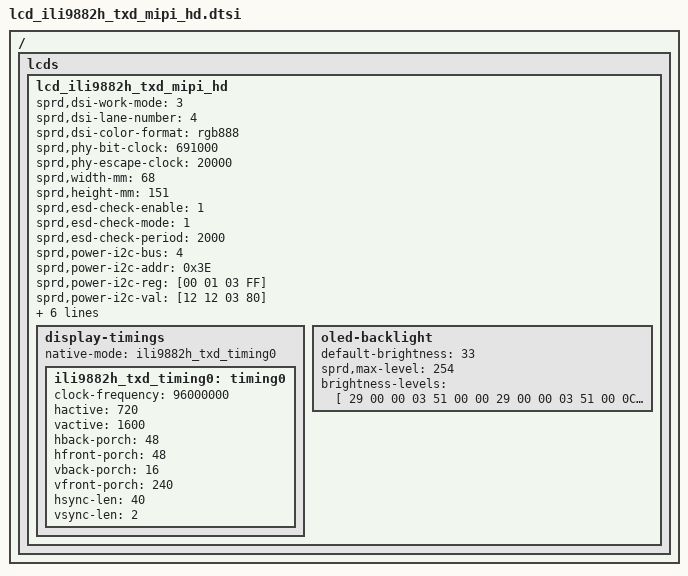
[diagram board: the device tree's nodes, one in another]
/*
 * ili9882h txd HD Scaling-Up LCD config dtsi file for spreadtrum
 *
 * Copyright (C) 2018, Spreadtrum Communications Inc.
 *
 * SPDX-License-Identifier: (GPL-2.0+ OR MIT)
 */

/ {
	fragment {
		target-path = "/";
		__overlay__ {
			lcds {
				lcd_ili9882h_txd_mipi_hd: lcd_ili9882h_txd_mipi_hd {
					sprd,dsi-work-mode = <3>; /* video burst mode*/
					sprd,dsi-lane-number = <4>;
					sprd,dsi-color-format = "rgb888";

					sprd,phy-bit-clock = <691000>;	/* kbps */    
					sprd,phy-escape-clock = <20000>;/* kHz */  

					sprd,width-mm = <68>;
					sprd,height-mm = <151>;
					
					sprd,esd-check-enable = <1>;
					sprd,esd-check-mode = <1>;
					sprd,esd-check-period = <2000>;
					//sprd,esd-check-register = <0xA>;
					//sprd,esd-check-value = <0x9c>;

					//sprd,use-oled-lp;

					sprd,power-i2c-bus = <4>;
        			sprd,power-i2c-addr = <0x3E>;
        			/*sprd,power-i2c-speed = <400000>;*/
        			sprd,power-i2c-reg = [00 01 03 FF];
        			sprd,power-i2c-val = [12 12 03 80];

					sprd,reset-on-sequence = <1 10>, <0 10>, <1 10>;
					sprd,reset-off-sequence = <1 10>;

					//sprd,use-dcs-write;

					sprd,initial-command = [
						29 00 00 04 FF 98 82 00
						13 00 00 02 35 00
						29 00 00 03 51 07 FF
						13 00 00 02 53 2C
						13 00 00 02 55 01
						03 3C 00 01 11
						29 00 00 04 FF 98 82 03
						29 00 00 02 83 B8
						29 00 00 04 FF 98 82 00
						03 14 00 01 29
						];

					sprd,sleep-in-command = [
						03 14 00 01 28
						03 78 00 01 10
						];

					display-timings {
						native-mode = <&ili9882h_txd_timing0>;

						ili9882h_txd_timing0: timing0 {
							clock-frequency = <96000000>;           
							hactive = <720>;
							vactive = <1600>;
							hback-porch = <48>;
							hfront-porch = <48>;
							vback-porch = <16>;
							vfront-porch = <240>;
							hsync-len = <40>;
							vsync-len = <2>;
						};
					};
			
					oled-backlight {			
						default-brightness = <33>;	
						sprd,max-level = <254>;
						brightness-levels = [				
            		    	29 00 00 03 51 00 00
							29 00 00 03 51 00 0C
							29 00 00 03 51 00 14
							29 00 00 03 51 00 1C
							29 00 00 03 51 00 25
							29 00 00 03 51 00 2D
							29 00 00 03 51 00 35
							29 00 00 03 51 00 3D
							29 00 00 03 51 00 45
							29 00 00 03 51 00 4D
							29 00 00 03 51 00 55
							29 00 00 03 51 00 5D
							29 00 00 03 51 00 65
							29 00 00 03 51 00 6D
							29 00 00 03 51 00 75
							29 00 00 03 51 00 7D
							29 00 00 03 51 00 85
							29 00 00 03 51 00 8D
							29 00 00 03 51 00 95
							29 00 00 03 51 00 9D
							29 00 00 03 51 00 A5
							29 00 00 03 51 00 AD
							29 00 00 03 51 00 B5
							29 00 00 03 51 00 BD
							29 00 00 03 51 00 C5
							29 00 00 03 51 00 CD
							29 00 00 03 51 00 D5
							29 00 00 03 51 00 DD
							29 00 00 03 51 00 E5
							29 00 00 03 51 00 EE
							29 00 00 03 51 00 F6
							29 00 00 03 51 00 FE
							29 00 00 03 51 01 06
							29 00 00 03 51 01 0E
							29 00 00 03 51 01 16
							29 00 00 03 51 01 1E
							29 00 00 03 51 01 26
							29 00 00 03 51 01 2E
							29 00 00 03 51 01 36
							29 00 00 03 51 01 3E
							29 00 00 03 51 01 46
							29 00 00 03 51 01 4E
							29 00 00 03 51 01 56
							29 00 00 03 51 01 5E
							29 00 00 03 51 01 66
							29 00 00 03 51 01 6E
							29 00 00 03 51 01 76
							29 00 00 03 51 01 7E
							29 00 00 03 51 01 86
							29 00 00 03 51 01 8E
							29 00 00 03 51 01 96
							29 00 00 03 51 01 9E
							29 00 00 03 51 01 A6
							29 00 00 03 51 01 AE
							29 00 00 03 51 01 B7
							29 00 00 03 51 01 BF
							29 00 00 03 51 01 C7
							29 00 00 03 51 01 CF
							29 00 00 03 51 01 D7
							29 00 00 03 51 01 DF
							29 00 00 03 51 01 E7
							29 00 00 03 51 01 EF
							29 00 00 03 51 01 F7
							29 00 00 03 51 01 FF
							29 00 00 03 51 02 07
							29 00 00 03 51 02 0F
							29 00 00 03 51 02 17
							29 00 00 03 51 02 1F
							29 00 00 03 51 02 27
							29 00 00 03 51 02 2F
							29 00 00 03 51 02 37
							29 00 00 03 51 02 3F
							29 00 00 03 51 02 47
							29 00 00 03 51 02 4F
							29 00 00 03 51 02 57
							29 00 00 03 51 02 5F
							29 00 00 03 51 02 67
							29 00 00 03 51 02 6F
							29 00 00 03 51 02 77
							29 00 00 03 51 02 80
							29 00 00 03 51 02 88
							29 00 00 03 51 02 90
							29 00 00 03 51 02 98
							29 00 00 03 51 02 A0
							29 00 00 03 51 02 A8
							29 00 00 03 51 02 B0
							29 00 00 03 51 02 B8
							29 00 00 03 51 02 C0
							29 00 00 03 51 02 C8
							29 00 00 03 51 02 D0
							29 00 00 03 51 02 D8
							29 00 00 03 51 02 E0
							29 00 00 03 51 02 E8
							29 00 00 03 51 02 F0
							29 00 00 03 51 02 F8
							29 00 00 03 51 03 00
							29 00 00 03 51 03 08
							29 00 00 03 51 03 10
							29 00 00 03 51 03 18
							29 00 00 03 51 03 20
							29 00 00 03 51 03 28
							29 00 00 03 51 03 30
							29 00 00 03 51 03 38
							29 00 00 03 51 03 40
							29 00 00 03 51 03 49
							29 00 00 03 51 03 51
							29 00 00 03 51 03 59
							29 00 00 03 51 03 61
							29 00 00 03 51 03 69
							29 00 00 03 51 03 71
							29 00 00 03 51 03 79
							29 00 00 03 51 03 81
							29 00 00 03 51 03 89
							29 00 00 03 51 03 91
							29 00 00 03 51 03 99
							29 00 00 03 51 03 A1
							29 00 00 03 51 03 A9
							29 00 00 03 51 03 B1
							29 00 00 03 51 03 B9
							29 00 00 03 51 03 C1
							29 00 00 03 51 03 C9
							29 00 00 03 51 03 D1
							29 00 00 03 51 03 D9
							29 00 00 03 51 03 E1
							29 00 00 03 51 03 E9
							29 00 00 03 51 03 F1
							29 00 00 03 51 03 F9
							29 00 00 03 51 04 01
							29 00 00 03 51 04 09
							29 00 00 03 51 04 12
							29 00 00 03 51 04 1A
							29 00 00 03 51 04 22
							29 00 00 03 51 04 2A
							29 00 00 03 51 04 32
							29 00 00 03 51 04 3A
							29 00 00 03 51 04 42
							29 00 00 03 51 04 4A
							29 00 00 03 51 04 52
							29 00 00 03 51 04 5A
							29 00 00 03 51 04 62
							29 00 00 03 51 04 6A
							29 00 00 03 51 04 72
							29 00 00 03 51 04 7A
							29 00 00 03 51 04 82
							29 00 00 03 51 04 8A
							29 00 00 03 51 04 92
							29 00 00 03 51 04 9A
							29 00 00 03 51 04 A2
							29 00 00 03 51 04 AA
							29 00 00 03 51 04 B2
							29 00 00 03 51 04 BA
							29 00 00 03 51 04 C2
							29 00 00 03 51 04 CA
							29 00 00 03 51 04 D2
							29 00 00 03 51 04 DB
							29 00 00 03 51 04 E3
							29 00 00 03 51 04 EB
							29 00 00 03 51 04 F3
							29 00 00 03 51 04 FB
							29 00 00 03 51 05 03
							29 00 00 03 51 05 0B
							29 00 00 03 51 05 13
							29 00 00 03 51 05 1B
							29 00 00 03 51 05 23
							29 00 00 03 51 05 2B
							29 00 00 03 51 05 33
							29 00 00 03 51 05 3B
							29 00 00 03 51 05 43
							29 00 00 03 51 05 4B
							29 00 00 03 51 05 53
							29 00 00 03 51 05 5B
							29 00 00 03 51 05 63
							29 00 00 03 51 05 6B
							29 00 00 03 51 05 73
							29 00 00 03 51 05 7B
							29 00 00 03 51 05 83
							29 00 00 03 51 05 8B
							29 00 00 03 51 05 93
							29 00 00 03 51 05 9B
							29 00 00 03 51 05 A4
							29 00 00 03 51 05 AC
							29 00 00 03 51 05 B4
							29 00 00 03 51 05 BC
							29 00 00 03 51 05 C4
							29 00 00 03 51 05 CC
							29 00 00 03 51 05 D4
							29 00 00 03 51 05 DC
							29 00 00 03 51 05 E4
							29 00 00 03 51 05 EC
							29 00 00 03 51 05 F4
							29 00 00 03 51 05 FC
							29 00 00 03 51 06 04
							29 00 00 03 51 06 0C
							29 00 00 03 51 06 14
							29 00 00 03 51 06 1C
							29 00 00 03 51 06 24
							29 00 00 03 51 06 2C
							29 00 00 03 51 06 34
							29 00 00 03 51 06 3C
							29 00 00 03 51 06 44
							29 00 00 03 51 06 4C
							29 00 00 03 51 06 54
							29 00 00 03 51 06 5C
							29 00 00 03 51 06 64
							29 00 00 03 51 06 6D
							29 00 00 03 51 06 75
							29 00 00 03 51 06 7D
							29 00 00 03 51 06 85
							29 00 00 03 51 06 8D
							29 00 00 03 51 06 95
							29 00 00 03 51 06 9D
							29 00 00 03 51 06 A5
							29 00 00 03 51 06 AD
							29 00 00 03 51 06 B5
							29 00 00 03 51 06 BD
							29 00 00 03 51 06 C5
							29 00 00 03 51 06 CD
							29 00 00 03 51 06 D5
							29 00 00 03 51 06 DD
							29 00 00 03 51 06 E5
							29 00 00 03 51 06 ED
							29 00 00 03 51 06 F5
							29 00 00 03 51 06 FD
							29 00 00 03 51 07 05
							29 00 00 03 51 07 0D
							29 00 00 03 51 07 15
							29 00 00 03 51 07 1D
							29 00 00 03 51 07 25
							29 00 00 03 51 07 2D
							29 00 00 03 51 07 36
							29 00 00 03 51 07 3E
							29 00 00 03 51 07 46
							29 00 00 03 51 07 4E
							29 00 00 03 51 07 56
							29 00 00 03 51 07 5E
							29 00 00 03 51 07 66
							29 00 00 03 51 07 6E
							29 00 00 03 51 07 76
							29 00 00 03 51 07 7E
							29 00 00 03 51 07 86
							29 00 00 03 51 07 8E
							29 00 00 03 51 07 96
							29 00 00 03 51 07 9E
							29 00 00 03 51 07 A6
							29 00 00 03 51 07 AE
							29 00 00 03 51 07 B6
							29 00 00 03 51 07 BE
							29 00 00 03 51 07 C6
							29 00 00 03 51 07 CE
							29 00 00 03 51 07 D6
							29 00 00 03 51 07 DE
							29 00 00 03 51 07 E6
							29 00 00 03 51 07 EE
							29 00 00 03 51 07 F6
							29 00 00 03 51 07 FF
						];
					};
				};
			};
		};
	};
};
